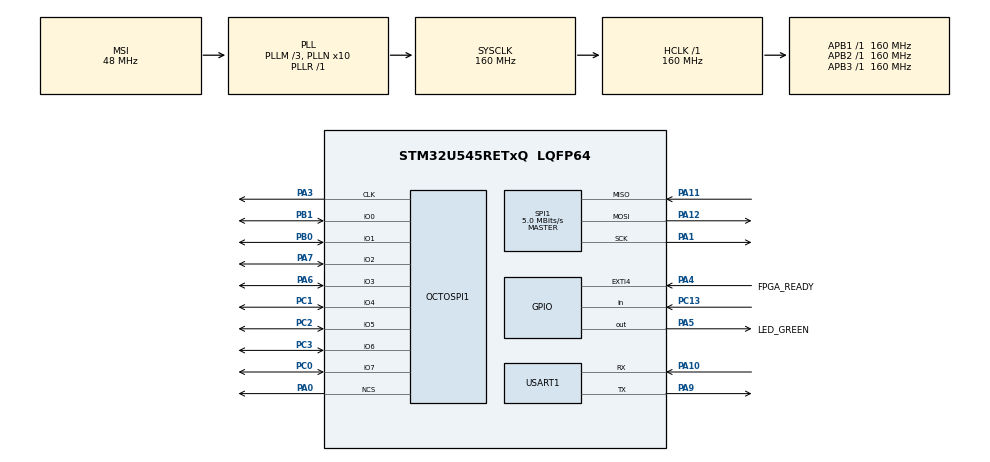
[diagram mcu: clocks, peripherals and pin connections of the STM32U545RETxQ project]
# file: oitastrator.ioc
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CORTEX_M33_NS.userName=CORTEX_M33
GPDMA1.DIRECTION_GPDMACH1=DMA_MEMORY_TO_PERIPH
GPDMA1.IPHANDLE_GPDMACH0-SIMPLEREQUEST_GPDMACH0=__NULL
GPDMA1.IPHANDLE_GPDMACH1-SIMPLEREQUEST_GPDMACH1=__NULL
GPDMA1.IPHANDLE_GPDMACH12-SIMPLEREQUEST_GPDMACH12=__NULL
GPDMA1.REQUEST_GPDMACH0=GPDMA1_REQUEST_SPI1_RX
GPDMA1.REQUEST_GPDMACH1=GPDMA1_REQUEST_SPI1_TX
GPDMA1.REQUEST_GPDMACH12=GPDMA1_REQUEST_OCTOSPI1
Mcu.Family=STM32U5
Mcu.Name=STM32U545RETxQ
Mcu.Package=LQFP64
NVIC.EXTI4_IRQn=true\:0\:0\:false\:false\:true\:true\:true\:true
NVIC.GPDMA1_Channel0_IRQn=true\:0\:0\:false\:false\:true\:false\:true\:true
NVIC.GPDMA1_Channel12_IRQn=true\:0\:0\:false\:false\:true\:false\:true\:true
NVIC.GPDMA1_Channel1_IRQn=true\:0\:0\:false\:false\:true\:false\:true\:true
NVIC.OCTOSPI1_IRQn=true\:0\:0\:false\:false\:true\:true\:true\:true
NVIC.PriorityGroup=NVIC_PRIORITYGROUP_4
NVIC.SPI1_IRQn=true\:0\:0\:false\:false\:true\:false\:true\:true
NVIC.USART1_IRQn=true\:0\:0\:false\:false\:true\:true\:true\:true
OCTOSPI1.ClockPrescaler=20
OCTOSPI1.FreeRunningClock=HAL_OSPI_FREERUNCLK_ENABLE
OCTOSPI1.MemoryType=HAL_OSPI_MEMTYPE_MACRONIX
OCTOSPI1.SampleShifting=HAL_OSPI_SAMPLE_SHIFTING_NONE
PA0.GPIO_PuPd=GPIO_PULLUP
PA0.GPIO_Speed_High_Default=GPIO_SPEED_FREQ_HIGH
PA0.Mode=octo_mode
PA0.Signal=OCTOSPI1_NCS
PA1.GPIO_Speed=GPIO_SPEED_FREQ_VERY_HIGH
PA1.Mode=Full_Duplex_Master
PA1.Signal=SPI1_SCK
PA10.Mode=Asynchronous
PA10.Signal=USART1_RX
PA11.GPIO_Speed=GPIO_SPEED_FREQ_VERY_HIGH
PA11.Mode=Full_Duplex_Master
PA11.Signal=SPI1_MISO
PA12.GPIO_Speed=GPIO_SPEED_FREQ_VERY_HIGH
PA12.Mode=Full_Duplex_Master
PA12.Signal=SPI1_MOSI
PA3.GPIO_PuPd=GPIO_NOPULL
PA3.GPIO_Speed_High_Default=GPIO_SPEED_FREQ_HIGH
PA3.Mode=octo_mode
PA3.Signal=OCTOSPI1_CLK
PA4.GPIO_Label=FPGA_READY
PA4.GPIO_PuPd=GPIO_PULLDOWN
PA4.Signal=GPXTI4
PA5.GPIO_Label=LED_GREEN
PA5.Signal=GPIO_Output
PA6.GPIO_Speed_High_Default=GPIO_SPEED_FREQ_HIGH
PA6.Mode=octo_mode
PA6.Signal=OCTOSPI1_IO3
PA7.GPIO_Speed_High_Default=GPIO_SPEED_FREQ_HIGH
PA7.Mode=octo_mode
PA7.Signal=OCTOSPI1_IO2
PA9.Mode=Asynchronous
PA9.Signal=USART1_TX
PB0.GPIO_Speed_High_Default=GPIO_SPEED_FREQ_HIGH
PB0.Mode=octo_mode
PB0.Signal=OCTOSPI1_IO1
PB1.GPIO_Speed_High_Default=GPIO_SPEED_FREQ_HIGH
PB1.Mode=octo_mode
PB1.Signal=OCTOSPI1_IO0
PB10.GPIO_Label=FPGA_ACK
PB10.Signal=LPGPIO_Input
PC0.GPIO_Speed_High_Default=GPIO_SPEED_FREQ_HIGH
PC0.Mode=octo_mode
PC0.Signal=OCTOSPI1_IO7
PC1.GPIO_Speed_High_Default=GPIO_SPEED_FREQ_HIGH
PC1.Mode=octo_mode
PC1.Signal=OCTOSPI1_IO4
PC13.Signal=GPIO_Input
PC14-OSC32_IN\ (PC14).Mode=LSE-External-Oscillator
PC14-OSC32_IN\ (PC14).Signal=RCC_OSC32_IN
PC15-OSC32_OUT\ (PC15).Mode=LSE-External-Oscillator
PC15-OSC32_OUT\ (PC15).Signal=RCC_OSC32_OUT
PC2.GPIO_Speed_High_Default=GPIO_SPEED_FREQ_HIGH
PC2.Mode=octo_mode
PC2.Signal=OCTOSPI1_IO5
PC3.GPIO_Speed_High_Default=GPIO_SPEED_FREQ_HIGH
PC3.Mode=octo_mode
PC3.Signal=OCTOSPI1_IO6
PWR.PowerMode=PWR_SMPS_SUPPLY
ProjectManager.HeapSize=0x200
ProjectManager.StackSize=0x400
ProjectManager.TargetToolchain=CMake
RCC.ADCFreq_Value=16000000
RCC.AHBFreq_Value=160000000
RCC.APB1Freq_Value=160000000
RCC.APB1TimFreq_Value=160000000
RCC.APB2Freq_Value=160000000
RCC.APB2TimFreq_Value=160000000
RCC.APB3Freq_Value=160000000
RCC.CortexFreq_Value=160000000
RCC.DACCLockSelectionVirtual=RCC_DAC1CLKSOURCE_LSI
RCC.DACCLockSelectionVirtualString=RCC_DAC1CLKSOURCE_LSI
RCC.EPOD_VALUE=48000000
RCC.HCLKFreq_Value=160000000
RCC.HSE_VALUE=16000000
RCC.HSI48_VALUE=48000000
RCC.HSI_VALUE=16000000
RCC.LSIDIV_VALUE=32000
RCC.MSIClockRange=RCC_MSIRANGE_0
RCC.MSI_VALUE=48000000
RCC.OCTOSPIMCLockSelection=RCC_OSPICLKSOURCE_PLL2
RCC.PLL1R=1
RCC.PLL2FRACN=0
RCC.PLL2N=10
RCC.PLL2Q=8
RCC.PLL2Source=RCC_PLLSOURCE_HSI
RCC.PLLFRACN=0
RCC.PLLM=3
RCC.PLLN=10
RCC.SYSCLKFreq_VALUE=160000000
RCC.SYSCLKSource=RCC_SYSCLKSOURCE_PLLCLK
RCC.USBFreq_Value=48000000
RCC.VCOOutputFreq_Value=160000000
SPI1.BaudRatePrescaler=SPI_BAUDRATEPRESCALER_32
SPI1.CalculateBaudRate=5.0 MBits/s
SPI1.DataSize=SPI_DATASIZE_8BIT
SPI1.Direction=SPI_DIRECTION_2LINES
SPI1.Mode=SPI_MODE_MASTER
SPI1.VirtualType=VM_MASTER
USART1.VirtualMode-Asynchronous=VM_ASYNC
VP_GPDMA1_VS_GPDMACH0.Mode=SIMPLEREQUEST_GPDMACH0
VP_GPDMA1_VS_GPDMACH1.Mode=SIMPLEREQUEST_GPDMACH1
VP_GPDMA1_VS_GPDMACH12.Mode=SIMPLEREQUEST_GPDMACH12
VP_ICACHE_VS_ICACHE.Mode=DirectMappedCache
VP_LPBAMQUEUE_VS_QUEUE.Mode=QUEUEMODE
VP_LPBAM_VS_SIG1.Mode=SmartRun
VP_LPBAM_VS_SIG4.Mode=LPDMA1
VP_MEMORYMAP_VS_MEMORYMAP.Mode=CurAppReg
VP_PWR_VS_LPOM.Mode=PowerOptimisation
VP_PWR_VS_SECSignals.Mode=Security/Privilege
board=custom

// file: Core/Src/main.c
/* USER CODE BEGIN Header */
/**
  ******************************************************************************
  * @file           : main.c
  * @brief          : Main program body
  ******************************************************************************
  * @attention
  *
  * Copyright (c) 2026 STMicroelectronics.
  * All rights reserved.
  *
  * This software is licensed under terms that can be found in the LICENSE file
  * in the root directory of this software component.
  * If no LICENSE file comes with this software, it is provided AS-IS.
  *
  ******************************************************************************
  */
/* USER CODE END Header */
#include "main.h"

/* USER CODE BEGIN Includes */
#include "myMain.h"

/* USER CODE END Includes */

OSPI_HandleTypeDef hospi1;
DMA_HandleTypeDef handle_GPDMA1_Channel12;

SPI_HandleTypeDef hspi1;
DMA_HandleTypeDef handle_GPDMA1_Channel1;
DMA_HandleTypeDef handle_GPDMA1_Channel0;

UART_HandleTypeDef huart1;

void SystemClock_Config(void);
static void SystemPower_Config(void);
static void MX_GPIO_Init(void);
static void MX_GPDMA1_Init(void);
static void MX_ICACHE_Init(void);
static void MX_OCTOSPI1_Init(void);
static void MX_USART1_UART_Init(void);
static void MX_SPI1_Init(void);

int main(void)
{

  /* MCU Configuration--------------------------------------------------------*/

  /* Reset of all peripherals, Initializes the Flash interface and the Systick. */
  HAL_Init();

  /* Configure the System Power */
  SystemPower_Config();

  /* Configure the system clock */
  SystemClock_Config();

  /* Initialize all configured peripherals */
  MX_GPIO_Init();
  MX_GPDMA1_Init();
  MX_ICACHE_Init();
  MX_OCTOSPI1_Init();
  MX_USART1_UART_Init();
  MX_SPI1_Init();
  /* USER CODE BEGIN 2 */

  myMain();
  // ANY code below should not run
  /* USER CODE END 2 */

  /* Infinite loop */
  while (1)
  {

  }
}

void SystemClock_Config(void)
{
  RCC_OscInitTypeDef RCC_OscInitStruct = {0};
  RCC_ClkInitTypeDef RCC_ClkInitStruct = {0};

  /** Configure the main internal regulator output voltage
  */
  if (HAL_PWREx_ControlVoltageScaling(PWR_REGULATOR_VOLTAGE_SCALE1) != HAL_OK)
  {
    Error_Handler();
  }

  /** Initializes the CPU, AHB and APB buses clocks
  */
  RCC_OscInitStruct.OscillatorType = RCC_OSCILLATORTYPE_HSI|RCC_OSCILLATORTYPE_MSI;
  RCC_OscInitStruct.HSIState = RCC_HSI_ON;
  RCC_OscInitStruct.HSICalibrationValue = RCC_HSICALIBRATION_DEFAULT;
  RCC_OscInitStruct.MSIState = RCC_MSI_ON;
  RCC_OscInitStruct.MSICalibrationValue = RCC_MSICALIBRATION_DEFAULT;
  RCC_OscInitStruct.MSIClockRange = RCC_MSIRANGE_0;
  RCC_OscInitStruct.PLL.PLLState = RCC_PLL_ON;
  RCC_OscInitStruct.PLL.PLLSource = RCC_PLLSOURCE_MSI;
  RCC_OscInitStruct.PLL.PLLMBOOST = RCC_PLLMBOOST_DIV4;
  RCC_OscInitStruct.PLL.PLLM = 3;
  RCC_OscInitStruct.PLL.PLLN = 10;
  RCC_OscInitStruct.PLL.PLLP = 2;
  RCC_OscInitStruct.PLL.PLLQ = 2;
  RCC_OscInitStruct.PLL.PLLR = 1;
  RCC_OscInitStruct.PLL.PLLRGE = RCC_PLLVCIRANGE_1;
  RCC_OscInitStruct.PLL.PLLFRACN = 0;
  if (HAL_RCC_OscConfig(&RCC_OscInitStruct) != HAL_OK)
  {
    Error_Handler();
  }

  /** Initializes the CPU, AHB and APB buses clocks
  */
  RCC_ClkInitStruct.ClockType = RCC_CLOCKTYPE_HCLK|RCC_CLOCKTYPE_SYSCLK
                              |RCC_CLOCKTYPE_PCLK1|RCC_CLOCKTYPE_PCLK2
                              |RCC_CLOCKTYPE_PCLK3;
  RCC_ClkInitStruct.SYSCLKSource = RCC_SYSCLKSOURCE_PLLCLK;
  RCC_ClkInitStruct.AHBCLKDivider = RCC_SYSCLK_DIV1;
  RCC_ClkInitStruct.APB1CLKDivider = RCC_HCLK_DIV1;
  RCC_ClkInitStruct.APB2CLKDivider = RCC_HCLK_DIV1;
  RCC_ClkInitStruct.APB3CLKDivider = RCC_HCLK_DIV1;

  if (HAL_RCC_ClockConfig(&RCC_ClkInitStruct, FLASH_LATENCY_4) != HAL_OK)
  {
    Error_Handler();
  }
}

/**
  * @brief Power Configuration
  * @retval None
  */
static void SystemPower_Config(void)
{

  /*
   * Switch to SMPS regulator instead of LDO
   */
  if (HAL_PWREx_ConfigSupply(PWR_SMPS_SUPPLY) != HAL_OK)
  {
    Error_Handler();
  }
}

static void MX_GPDMA1_Init(void)
{

  /* Peripheral clock enable */
  __HAL_RCC_GPDMA1_CLK_ENABLE();

  /* GPDMA1 interrupt Init */
    HAL_NVIC_SetPriority(GPDMA1_Channel0_IRQn, 0, 0);
    HAL_NVIC_EnableIRQ(GPDMA1_Channel0_IRQn);
    HAL_NVIC_SetPriority(GPDMA1_Channel1_IRQn, 0, 0);
    HAL_NVIC_EnableIRQ(GPDMA1_Channel1_IRQn);
    HAL_NVIC_SetPriority(GPDMA1_Channel12_IRQn, 0, 0);
    HAL_NVIC_EnableIRQ(GPDMA1_Channel12_IRQn);

}

static void MX_ICACHE_Init(void)
{

  /** Enable instruction cache in 1-way (direct mapped cache)
  */
  if (HAL_ICACHE_ConfigAssociativityMode(ICACHE_1WAY) != HAL_OK)
  {
    Error_Handler();
  }
  if (HAL_ICACHE_Enable() != HAL_OK)
  {
    Error_Handler();
  }

}

static void MX_OCTOSPI1_Init(void)
{

  /* OCTOSPI1 parameter configuration*/
  hospi1.Instance = OCTOSPI1;
  hospi1.Init.FifoThreshold = 1;
  hospi1.Init.DualQuad = HAL_OSPI_DUALQUAD_DISABLE;
  hospi1.Init.MemoryType = HAL_OSPI_MEMTYPE_MACRONIX;
  hospi1.Init.DeviceSize = 32;
  hospi1.Init.ChipSelectHighTime = 1;
  hospi1.Init.FreeRunningClock = HAL_OSPI_FREERUNCLK_ENABLE;
  hospi1.Init.ClockMode = HAL_OSPI_CLOCK_MODE_0;
  hospi1.Init.WrapSize = HAL_OSPI_WRAP_NOT_SUPPORTED;
  hospi1.Init.ClockPrescaler = 20;
  hospi1.Init.SampleShifting = HAL_OSPI_SAMPLE_SHIFTING_NONE;
  hospi1.Init.DelayHoldQuarterCycle = HAL_OSPI_DHQC_DISABLE;
  hospi1.Init.ChipSelectBoundary = 0;
  hospi1.Init.MaxTran = 0;
  hospi1.Init.Refresh = 0;
  if (HAL_OSPI_Init(&hospi1) != HAL_OK)
  {
    Error_Handler();
  }

}

static void MX_SPI1_Init(void)
{

  SPI_AutonomousModeConfTypeDef HAL_SPI_AutonomousMode_Cfg_Struct = {0};

  /* SPI1 parameter configuration*/
  hspi1.Instance = SPI1;
  hspi1.Init.Mode = SPI_MODE_MASTER;
  hspi1.Init.Direction = SPI_DIRECTION_2LINES;
  hspi1.Init.DataSize = SPI_DATASIZE_8BIT;
  hspi1.Init.CLKPolarity = SPI_POLARITY_LOW;
  hspi1.Init.CLKPhase = SPI_PHASE_1EDGE;
  hspi1.Init.NSS = SPI_NSS_SOFT;
  hspi1.Init.BaudRatePrescaler = SPI_BAUDRATEPRESCALER_32;
  hspi1.Init.FirstBit = SPI_FIRSTBIT_MSB;
  hspi1.Init.TIMode = SPI_TIMODE_DISABLE;
  hspi1.Init.CRCCalculation = SPI_CRCCALCULATION_DISABLE;
  hspi1.Init.CRCPolynomial = 0x7;
  hspi1.Init.NSSPMode = SPI_NSS_PULSE_ENABLE;
  hspi1.Init.NSSPolarity = SPI_NSS_POLARITY_LOW;
  hspi1.Init.FifoThreshold = SPI_FIFO_THRESHOLD_01DATA;
  hspi1.Init.MasterSSIdleness = SPI_MASTER_SS_IDLENESS_00CYCLE;
  hspi1.Init.MasterInterDataIdleness = SPI_MASTER_INTERDATA_IDLENESS_00CYCLE;
  hspi1.Init.MasterReceiverAutoSusp = SPI_MASTER_RX_AUTOSUSP_DISABLE;
  hspi1.Init.MasterKeepIOState = SPI_MASTER_KEEP_IO_STATE_DISABLE;
  hspi1.Init.IOSwap = SPI_IO_SWAP_DISABLE;
  hspi1.Init.ReadyMasterManagement = SPI_RDY_MASTER_MANAGEMENT_INTERNALLY;
  hspi1.Init.ReadyPolarity = SPI_RDY_POLARITY_HIGH;
  if (HAL_SPI_Init(&hspi1) != HAL_OK)
  {
    Error_Handler();
  }
  HAL_SPI_AutonomousMode_Cfg_Struct.TriggerState = SPI_AUTO_MODE_DISABLE;
  HAL_SPI_AutonomousMode_Cfg_Struct.TriggerSelection = SPI_GRP1_GPDMA_CH0_TCF_TRG;
  HAL_SPI_AutonomousMode_Cfg_Struct.TriggerPolarity = SPI_TRIG_POLARITY_RISING;
  if (HAL_SPIEx_SetConfigAutonomousMode(&hspi1, &HAL_SPI_AutonomousMode_Cfg_Struct) != HAL_OK)
  {
    Error_Handler();
  }

}

static void MX_USART1_UART_Init(void)
{

  huart1.Instance = USART1;
  huart1.Init.BaudRate = 115200;
  huart1.Init.WordLength = UART_WORDLENGTH_8B;
  huart1.Init.StopBits = UART_STOPBITS_1;
  huart1.Init.Parity = UART_PARITY_NONE;
  huart1.Init.Mode = UART_MODE_TX_RX;
  huart1.Init.HwFlowCtl = UART_HWCONTROL_NONE;
  huart1.Init.OverSampling = UART_OVERSAMPLING_16;
  huart1.Init.OneBitSampling = UART_ONE_BIT_SAMPLE_DISABLE;
  huart1.Init.ClockPrescaler = UART_PRESCALER_DIV1;
  huart1.AdvancedInit.AdvFeatureInit = UART_ADVFEATURE_NO_INIT;
  if (HAL_UART_Init(&huart1) != HAL_OK)
  {
    Error_Handler();
  }
  if (HAL_UARTEx_SetTxFifoThreshold(&huart1, UART_TXFIFO_THRESHOLD_1_8) != HAL_OK)
  {
    Error_Handler();
  }
  if (HAL_UARTEx_SetRxFifoThreshold(&huart1, UART_RXFIFO_THRESHOLD_1_8) != HAL_OK)
  {
    Error_Handler();
  }
  if (HAL_UARTEx_DisableFifoMode(&huart1) != HAL_OK)
  {
    Error_Handler();
  }

}

static void MX_GPIO_Init(void)
{
  GPIO_InitTypeDef GPIO_InitStruct = {0};

  /* GPIO Ports Clock Enable */
  __HAL_RCC_GPIOC_CLK_ENABLE();
  __HAL_RCC_GPIOA_CLK_ENABLE();
  __HAL_RCC_GPIOB_CLK_ENABLE();
  __HAL_RCC_LPGPIO1_CLK_ENABLE();

  /*Configure GPIO pin Output Level */
  HAL_GPIO_WritePin(LED_GREEN_GPIO_Port, LED_GREEN_Pin, GPIO_PIN_RESET);

  /*Configure GPIO pin : PC13 */
  GPIO_InitStruct.Pin = GPIO_PIN_13;
  GPIO_InitStruct.Mode = GPIO_MODE_INPUT;
  GPIO_InitStruct.Pull = GPIO_NOPULL;
  HAL_GPIO_Init(GPIOC, &GPIO_InitStruct);

  /*Configure GPIO pin : FPGA_READY_Pin */
  GPIO_InitStruct.Pin = FPGA_READY_Pin;
  GPIO_InitStruct.Mode = GPIO_MODE_IT_RISING;
  GPIO_InitStruct.Pull = GPIO_PULLDOWN;
  HAL_GPIO_Init(FPGA_READY_GPIO_Port, &GPIO_InitStruct);

  /*Configure GPIO pin : LED_GREEN_Pin */
  GPIO_InitStruct.Pin = LED_GREEN_Pin;
  GPIO_InitStruct.Mode = GPIO_MODE_OUTPUT_PP;
  GPIO_InitStruct.Pull = GPIO_NOPULL;
  GPIO_InitStruct.Speed = GPIO_SPEED_FREQ_LOW;
  HAL_GPIO_Init(LED_GREEN_GPIO_Port, &GPIO_InitStruct);

  /*Configure LPGPIO pin : Pin4 */
  GPIO_InitStruct.Pin = GPIO_PIN_4;
  GPIO_InitStruct.Mode = GPIO_MODE_INPUT;
  GPIO_InitStruct.Pull = GPIO_NOPULL;
  HAL_GPIO_Init(LPGPIO1, &GPIO_InitStruct);

  /* EXTI interrupt init*/
  HAL_NVIC_SetPriority(EXTI4_IRQn, 0, 0);
  HAL_NVIC_EnableIRQ(EXTI4_IRQn);

}

void Error_Handler(void)
{
  __disable_irq();
  while (1)
  {
  }
}
